# ESP32-S2 register map
Vendor: ESPRESSIF SYSTEMS (SHANGHAI) CO., LTD.; Series: ESP32 S-Series; File version: 20
CPU: Xtensa LX7 r0p0, little endian, no MPU, no FPU, 0 interrupt priority bits
Address unit: 32 bits
Registers are 32-bit, read-write, reset 0x0 unless marked. A register's access mark holds for its fields unless they carry their own. Offsets are from the block's base; [hi:lo] are bit positions.

## UART0 — UART (Universal Asynchronous Receiver-Transmitter) Controller 0
Base 0x3F400000
Same registers: UART1 0x3F410000
0x00 FIFO ro — FIFO data register
  [7:0] RXFIFO_RD_BYTE — UART 0 accesses FIFO via this register.
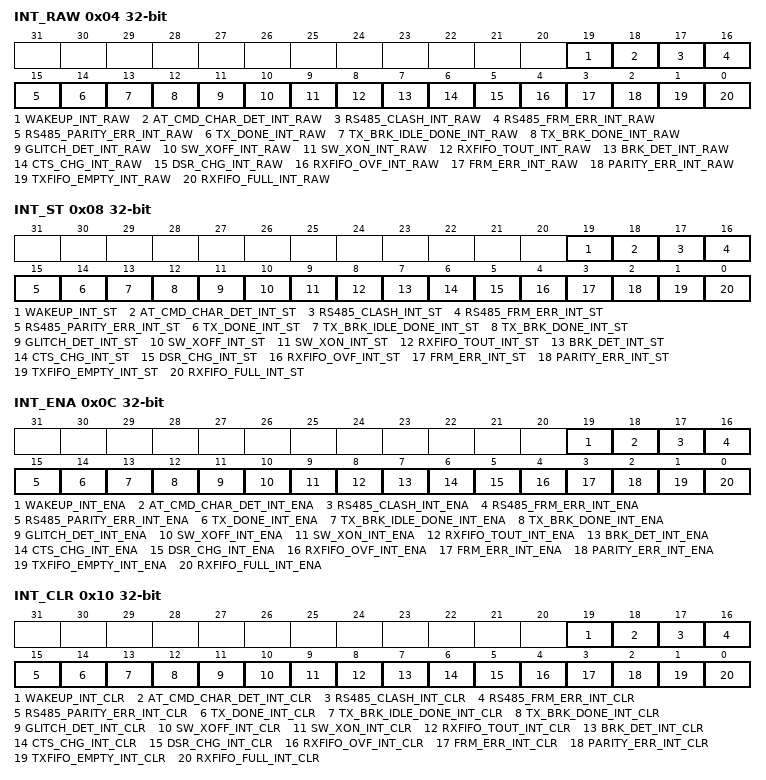
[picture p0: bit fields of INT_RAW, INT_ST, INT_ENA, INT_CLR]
0x04 INT_RAW ro — Raw interrupt status
  [19] WAKEUP_INT_RAW — This interrupt raw bit turns to high level when input RXD edge changes more times than what UART_ACTIVE_THRESHOLD specifies in Light-sleep mode.
  [18] AT_CMD_CHAR_DET_INT_RAW — This interrupt raw bit turns to high level when the receiver detects the configured UART_AT_CMD CHAR.
  [17] RS485_CLASH_INT_RAW — This interrupt raw bit turns to high level when a collision is detected between the transmitter and the receiver in RS485 mode.
  [16] RS485_FRM_ERR_INT_RAW — This interrupt raw bit turns to high level when the receiver detects a data frame error from the echo of the transmitter in RS485 mode.
  [15] RS485_PARITY_ERR_INT_RAW — This interrupt raw bit turns to high level when the receiver detects a parity error from the echo of the transmitter in RS485 mode.
  [14] TX_DONE_INT_RAW — This interrupt raw bit turns to high level when the transmitter has sent out all data in FIFO.
  [13] TX_BRK_IDLE_DONE_INT_RAW — This interrupt raw bit turns to high level when the transmitter has kept the shortest duration after sending the last data.
  [12] TX_BRK_DONE_INT_RAW — This interrupt raw bit turns to high level when the transmitter completes sending NULL characters, after all data in TX FIFO are sent.
  [11] GLITCH_DET_INT_RAW — This interrupt raw bit turns to high level when the receiver detects a glitch in the middle of a start bit.
  [10] SW_XOFF_INT_RAW — This interrupt raw bit turns to high level when the receiver receives an XOFF character and UART_SW_FLOW_CON_EN is set to 1.
  [9] SW_XON_INT_RAW — This interrupt raw bit turns to high level when the receiver receives an XON character and UART_SW_FLOW_CON_EN is set to 1.
  [8] RXFIFO_TOUT_INT_RAW — This interrupt raw bit turns to high level when the receiver takes more time than UART_RX_TOUT_THRHD to receive a byte.
  [7] BRK_DET_INT_RAW — This interrupt raw bit turns to high level when the receiver detects a 0 after the stop bit.
  [6] CTS_CHG_INT_RAW — This interrupt raw bit turns to high level when the receiver detects the edge change of CTSn signal.
  [5] DSR_CHG_INT_RAW — This interrupt raw bit turns to high level when the receiver detects the edge change of DSRn signal.
  [4] RXFIFO_OVF_INT_RAW — This interrupt raw bit turns to high level when the receiver receives more data than the capacity of RX FIFO.
  [3] FRM_ERR_INT_RAW — This interrupt raw bit turns to high level when the receiver detects a data frame error.
  [2] PARITY_ERR_INT_RAW — This interrupt raw bit turns to high level when the receiver detects a parity error in the data.
  [1] TXFIFO_EMPTY_INT_RAW — This interrupt raw bit turns to high level when the amount of data in TX FIFO is less than what UART_TXFIFO_EMPTY_THRHD specifies.
  [0] RXFIFO_FULL_INT_RAW — This interrupt raw bit turns to high level when the receiver receives more data than what UART_RXFIFO_FULL_THRHD specifies.
0x08 INT_ST ro — Masked interrupt status
  [19] WAKEUP_INT_ST — This is the status bit for UART_WAKEUP_INT when UART_WAKEUP_INT_ENA is set to 1.
  [18] AT_CMD_CHAR_DET_INT_ST — This is the status bit for UART_AT_CMD_CHAR_DET_INT when UART_AT_CMD_CHAR_DET_INT_ENA is set to 1.
  [17] RS485_CLASH_INT_ST — This is the status bit for UART_RS485_CLASH_INT when UART_RS485_CLASH_INT_ENA is set to 1.
  [16] RS485_FRM_ERR_INT_ST — This is the status bit for UART_RS485_FRM_ERR_INT when UART_RS485_FRM_ERR_INT_ENA is set to 1.
  [15] RS485_PARITY_ERR_INT_ST — This is the status bit for UART_RS485_PARITY_ERR_INT when UART_RS485_PARITY_INT_ENA is set to 1.
  [14] TX_DONE_INT_ST — This is the status bit for UART_TX_DONE_INT when UART_TX_DONE_INT_ENA is set to 1.
  [13] TX_BRK_IDLE_DONE_INT_ST — This is the status bit for UART_TX_BRK_IDLE_DONE_INT when UART_TX_BRK_IDLE_DONE_INT_ENA is set to 1.
  [12] TX_BRK_DONE_INT_ST — This is the status bit for UART_TX_BRK_DONE_INT when UART_TX_BRK_DONE_INT_ENA is set to 1.
  [11] GLITCH_DET_INT_ST — This is the status bit for UART_GLITCH_DET_INT when UART_GLITCH_DET_INT_ENA is set to 1.
  [10] SW_XOFF_INT_ST — This is the status bit for UART_SW_XOFF_INT when UART_SW_XOFF_INT_ENA is set to 1.
  [9] SW_XON_INT_ST — This is the status bit for UART_SW_XON_INT when UART_SW_XON_INT_ENA is set to 1.
  [8] RXFIFO_TOUT_INT_ST — This is the status bit for UART_RXFIFO_TOUT_INT when UART_RXFIFO_TOUT_INT_ENA is set to 1.
  [7] BRK_DET_INT_ST — This is the status bit for UART_BRK_DET_INT when UART_BRK_DET_INT_ENA is set to 1.
  [6] CTS_CHG_INT_ST — This is the status bit for UART_CTS_CHG_INT when UART_CTS_CHG_INT_ENA is set to 1.
  [5] DSR_CHG_INT_ST — This is the status bit for UART_DSR_CHG_INT when UART_DSR_CHG_INT_ENA is set to 1.
  [4] RXFIFO_OVF_INT_ST — This is the status bit for UART_RXFIFO_OVF_INT when UART_RXFIFO_OVF_INT_ENA is set to 1.
  [3] FRM_ERR_INT_ST — This is the status bit for UART_FRM_ERR_INT when UART_FRM_ERR_INT_ENA is set to 1.
  [2] PARITY_ERR_INT_ST — This is the status bit for UART_PARITY_ERR_INT when UART_PARITY_ERR_INT_ENA is set to 1.
  [1] TXFIFO_EMPTY_INT_ST — This is the status bit for UART_TXFIFO_EMPTY_INT when UART_TXFIFO_EMPTY_INT_ENA is set to 1.
  [0] RXFIFO_FULL_INT_ST — This is the status bit for UART_RXFIFO_FULL_INT when UART_RXFIFO_FULL_INT_ENA is set to 1.
0x0C INT_ENA — Interrupt enable bits
  [19] WAKEUP_INT_ENA — This is the enable bit for UART_WAKEUP_INT.
  [18] AT_CMD_CHAR_DET_INT_ENA — This is the enable bit for UART_AT_CMD_CHAR_DET_INT.
  [17] RS485_CLASH_INT_ENA — This is the enable bit for UART_RS485_CLASH_INT.
  [16] RS485_FRM_ERR_INT_ENA — This is the enable bit for UART_RS485_PARITY_ERR_INT.
  [15] RS485_PARITY_ERR_INT_ENA — This is the enable bit for UART_RS485_PARITY_ERR_INT.
  [14] TX_DONE_INT_ENA — This is the enable bit for UART_TX_DONE_INT.
  [13] TX_BRK_IDLE_DONE_INT_ENA — This is the enable bit for UART_TX_BRK_IDLE_DONE_INT.
  [12] TX_BRK_DONE_INT_ENA — This is the enable bit for UART_TX_BRK_DONE_INT.
  [11] GLITCH_DET_INT_ENA — This is the enable bit for UART_GLITCH_DET_INT.
  [10] SW_XOFF_INT_ENA — This is the enable bit for UART_SW_XOFF_INT.
  [9] SW_XON_INT_ENA — This is the enable bit for UART_SW_XON_INT.
  [8] RXFIFO_TOUT_INT_ENA — This is the enable bit for UART_RXFIFO_TOUT_INT.
  [7] BRK_DET_INT_ENA — This is the enable bit for UART_BRK_DET_INT.
  [6] CTS_CHG_INT_ENA — This is the enable bit for UART_CTS_CHG_INT.
  [5] DSR_CHG_INT_ENA — This is the enable bit for UART_DSR_CHG_INT.
  [4] RXFIFO_OVF_INT_ENA — This is the enable bit for UART_RXFIFO_OVF_INT.
  [3] FRM_ERR_INT_ENA — This is the enable bit for UART_FRM_ERR_INT.
  [2] PARITY_ERR_INT_ENA — This is the enable bit for UART_PARITY_ERR_INT.
  [1] TXFIFO_EMPTY_INT_ENA — This is the enable bit for UART_TXFIFO_EMPTY_INT.
  [0] RXFIFO_FULL_INT_ENA — This is the enable bit for UART_RXFIFO_FULL_INT.
0x10 INT_CLR wo — Interrupt clear bits
  [19] WAKEUP_INT_CLR — Set this bit to clear UART_WAKEUP_INT interrupt.
  [18] AT_CMD_CHAR_DET_INT_CLR — Set this bit to clear UART_AT_CMD_CHAR_DET_INT interrupt.
  [17] RS485_CLASH_INT_CLR — Set this bit to clear UART_RS485_CLASH_INT interrupt.
  [16] RS485_FRM_ERR_INT_CLR — Set this bit to clear UART_RS485_FRM_ERR_INT interrupt.
  [15] RS485_PARITY_ERR_INT_CLR — Set this bit to clear UART_RS485_PARITY_ERR_INT interrupt.
  [14] TX_DONE_INT_CLR — Set this bit to clear UART_TX_DONE_INT interrupt.
  [13] TX_BRK_IDLE_DONE_INT_CLR — Set this bit to clear UART_TX_BRK_IDLE_DONE_INT interrupt.
  [12] TX_BRK_DONE_INT_CLR — Set this bit to clear UART_TX_BRK_DONE_INT interrupt.
  [11] GLITCH_DET_INT_CLR — Set this bit to clear UART_GLITCH_DET_INT interrupt.
  [10] SW_XOFF_INT_CLR — Set this bit to clear UART_SW_XOFF_INT interrupt.
  [9] SW_XON_INT_CLR — Set this bit to clear UART_SW_XON_INT interrupt.
  [8] RXFIFO_TOUT_INT_CLR — Set this bit to clear UART_RXFIFO_TOUT_INT interrupt.
  [7] BRK_DET_INT_CLR — Set this bit to clear UART_BRK_DET_INT interrupt.
  [6] CTS_CHG_INT_CLR — Set this bit to clear UART_CTS_CHG_INT interrupt.
  [5] DSR_CHG_INT_CLR — Set this bit to clear UART_DSR_CHG_INT interrupt.
  [4] RXFIFO_OVF_INT_CLR — Set this bit to clear UART_UART_RXFIFO_OVF_INT interrupt.
  [3] FRM_ERR_INT_CLR — Set this bit to clear UART_FRM_ERR_INT interrupt.
  [2] PARITY_ERR_INT_CLR — Set this bit to clear UART_PARITY_ERR_INT interrupt.
  [1] TXFIFO_EMPTY_INT_CLR — Set this bit to clear UART_TXFIFO_EMPTY_INT interrupt.
  [0] RXFIFO_FULL_INT_CLR — Set this bit to clear UART_THE RXFIFO_FULL_INT interrupt.
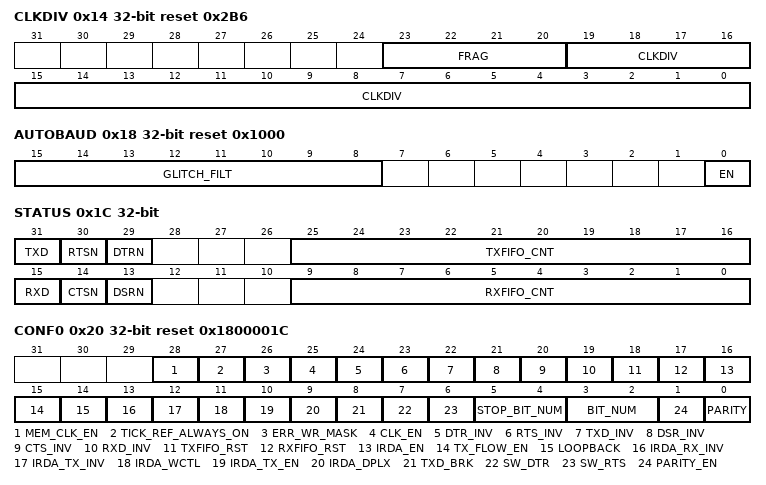
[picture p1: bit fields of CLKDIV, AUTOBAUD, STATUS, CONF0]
0x14 CLKDIV reset 0x2B6 — Clock divider configuration
  [23:20] FRAG — The fractional part of the frequency divisor.
  [19:0] CLKDIV — The integral part of the frequency divisor.
0x18 AUTOBAUD reset 0x1000 — Autobaud configuration register
  [15:8] GLITCH_FILT — When input pulse width is lower than this value, the pulse is ignored. This register is used in autobaud detection.
  [0] EN — This is the enable bit for baud rate detection.
0x1C STATUS ro — UART status register
  [31] TXD — This bit represents the level of the internal UART TXD signal.
  [30] RTSN — This bit represents the level of the internal UART RTS signal.
  [29] DTRN — This bit represents the level of the internal UART DTR signal.
  [25:16] TXFIFO_CNT — Stores the number of data bytes in TX FIFO.
  [15] RXD — This register represents the level of the internal UART RXD signal.
  [14] CTSN — This register represents the level of the internal UART CTS signal.
  [13] DSRN — This register represents the level of the internal UART DSR signal.
  [9:0] RXFIFO_CNT — Stores the number of valid data bytes in RX FIFO.
0x20 CONF0 reset 0x1800001C — Configuration register 0
  [28] MEM_CLK_EN — The signal to enable UART RAM clock gating. 1: UART RAM powers on, the data of which can be read and written. 0: UART RAM powers down.
  [27] TICK_REF_ALWAYS_ON — This register is used to select the clock. 1: APB_CLK. 0: REF_TICK.
  [26] ERR_WR_MASK — 1: The receiver stops storing data into FIFO when data is wrong. 0: The receiver stores the data even if the received data is wrong.
  [25] CLK_EN — 1: Force clock on for registers. 0: Support clock only when application writes registers.
  [24] DTR_INV — Set this bit to invert the level of UART DTR signal.
  [23] RTS_INV — Set this bit to invert the level of UART RTS signal.
  [22] TXD_INV — Set this bit to invert the level of UART TXD signal.
  [21] DSR_INV — Set this bit to invert the level of UART DSR signal.
  [20] CTS_INV — Set this bit to invert the level of UART CTS signal.
  [19] RXD_INV — Set this bit to invert the level of UART RXD signal.
  [18] TXFIFO_RST — Set this bit to reset the UART TX FIFO.
  [17] RXFIFO_RST — Set this bit to reset the UART RX FIFO.
  [16] IRDA_EN — Set this bit to enable IrDA protocol.
  [15] TX_FLOW_EN — Set this bit to enable flow control function for the transmitter.
  [14] LOOPBACK — Set this bit to enable UART loopback test mode.
  [13] IRDA_RX_INV — Set this bit to invert the level of IrDA receiver.
  [12] IRDA_TX_INV — Set this bit to invert the level of IrDA transmitter.
  [11] IRDA_WCTL — 1: The IrDA transmitter's 11th bit is the same as 10th bit. 0: Set IrDA transmitter's 11th bit to 0.
  [10] IRDA_TX_EN — This is the start enable bit for IrDA transmitter.
  [9] IRDA_DPLX — Set this bit to enable IrDA loopback mode.
  [8] TXD_BRK — Set this bit to enable the transmitter to send NULL characters when the process of sending data is done.
  [7] SW_DTR — This register is used to configure the software DTR signal which is used in software flow control.
  [6] SW_RTS — This register is used to configure the software RTS signal which is used in software flow control.
  [5:4] STOP_BIT_NUM — This register is used to set the length of stop bit. 1: 1 bit. 2: 1.5 bits. 3: 2 bits.
  [3:2] BIT_NUM — This register is used to set the length of data. 0: 5 bits. 1: 6 bits. 2: 7 bits. 3: 8 bits.
  [1] PARITY_EN — Set this bit to enable UART parity check.
  [0] PARITY — This register is used to configure the parity check mode. 0: even. 1: odd.
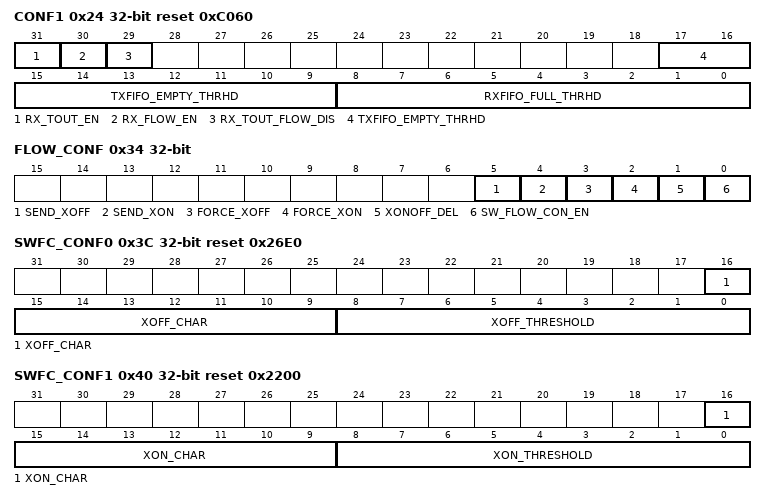
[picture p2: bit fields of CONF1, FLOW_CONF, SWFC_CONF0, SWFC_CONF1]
0x24 CONF1 reset 0xC060 — Configuration register 1
  [31] RX_TOUT_EN — This is the enable bit for UART receiver's timeout function.
  [30] RX_FLOW_EN — This is the flow enable bit for UART receiver. 1: Choose software flow control with configuring sw_rts signal. 0: Disable software flow control.
  [29] RX_TOUT_FLOW_DIS — Set this bit to stop accumulating idle_cnt when hardware flow control works.
  [17:9] TXFIFO_EMPTY_THRHD — An UART_TXFIFO_EMPTY_INT interrupt is generated when the number of data bytes in TX FIFO is less than this register's value.
  [8:0] RXFIFO_FULL_THRHD — An UART_RXFIFO_FULL_INT interrupt is generated when the receiver receives more data than this register’s value.
0x28 LOWPULSE ro reset 0xFFFFF — Autobaud minimum low pulse duration register
  [19:0] MIN_CNT — This register stores the value of the minimum duration time of the low level pulse. It is used in baud rate detection.
0x2C HIGHPULSE ro reset 0xFFFFF — Autobaud minimum high pulse duration register
  [19:0] MIN_CNT — This register stores the value of the maximum duration time for the high level pulse. It is used in baud rate detection.
0x30 RXD_CNT ro — Autobaud edge change count register
  [9:0] RXD_EDGE_CNT — This register stores the count of RXD edge change. It is used in baud rate detection. As baud rate registers UART_REG_LOWPULSE_MIN_CNT, UART_REG_HIGHPULSE_MIN_CNT, UART_REG_POSEDGE_MIN_CNT, and UART_REG_NEGEDGE_MIN_CNT always record the minimal value, UART_REG_RXD_EDGE_CNT indicates the statistic number of RXD edge to find out the minimal value for these baud rate registers.
0x34 FLOW_CONF — Software flow control configuration
  [5] SEND_XOFF — Set this bit to send an XOFF character. This bit is cleared by hardware automatically.
  [4] SEND_XON — Set this bit to send an XON character. This bit is cleared by hardware automatically.
  [3] FORCE_XOFF — Set this bit to stop the transmitter from sending data.
  [2] FORCE_XON — Set this bit to force the transmitter to send data.
  [1] XONOFF_DEL — Set this bit to remove flow control characters from the received data.
  [0] SW_FLOW_CON_EN — Set this bit to enable software flow control. When UART receives flow control characters XON or XOFF, which can be configured by UART_XON_CHAR or UART_XOFF_CHAR respectively, UART_SW_XON_INT or UART_SW_XOFF_INT interrupts can be triggered if enabled.
0x38 SLEEP_CONF reset 0xF0 — Sleep mode configuration
  [9:0] ACTIVE_THRESHOLD — The UART is activated from Light-sleep mode when the input RXD edge changes more times than this register's value.
0x3C SWFC_CONF0 reset 0x26E0 — Software flow control character configuration
  [16:9] XOFF_CHAR — This register stores the XOFF flow control character.
  [8:0] XOFF_THRESHOLD — When the number of data bytes in RX FIFO is more than this register's value with UART_SW_FLOW_CON_EN set to 1, the transmitter sends an XOFF character.
0x40 SWFC_CONF1 reset 0x2200 — Software flow-control character configuration
  [16:9] XON_CHAR — This register stores the XON flow control character.
  [8:0] XON_THRESHOLD — When the number of data bytes in RX FIFO is less than this register's value with UART_SW_FLOW_CON_EN set to 1, the transmitter sends an XON character.
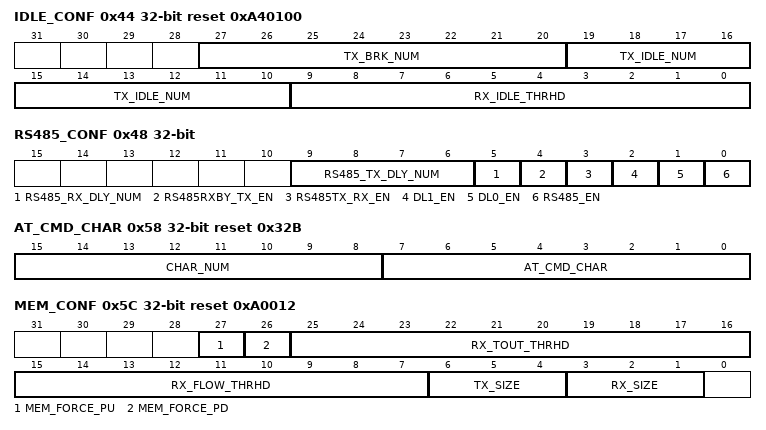
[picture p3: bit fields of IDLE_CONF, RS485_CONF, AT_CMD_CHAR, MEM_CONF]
0x44 IDLE_CONF reset 0xA40100 — Frame end idle time configuration
  [27:20] TX_BRK_NUM — This register is used to configure the number of 0 to be sent after the process of sending data is done. It is active when UART_TXD_BRK is set to 1.
  [19:10] TX_IDLE_NUM — This register is used to configure the duration time between transfers, in the unit of bit time (the time it takes to transfer one bit).
  [9:0] RX_IDLE_THRHD — A frame end signal is generated when the receiver takes more time to receive one byte data than this register's value, in the unit of bit time (the time it takes to transfer one bit).
0x48 RS485_CONF — RS485 mode configuration
  [9:6] RS485_TX_DLY_NUM — This register is used to delay the transmitter's internal data signal.
  [5] RS485_RX_DLY_NUM — This register is used to delay the receiver's internal data signal.
  [4] RS485RXBY_TX_EN — 1: enable RS485 transmitter to send data when RS485 receiver line is busy. 0: RS485 transmitter should not send data when its receiver is busy.
  [3] RS485TX_RX_EN — Set this bit to enable the receiver could receive data when the transmitter is transmitting data in RS485 mode.
  [2] DL1_EN — Set this bit to delay the stop bit by 1 bit.
  [1] DL0_EN — Set this bit to delay the stop bit by 1 bit.
  [0] RS485_EN — Set this bit to choose RS485 mode.
0x4C AT_CMD_PRECNT reset 0x901 — Pre-sequence timing configuration
  [15:0] PRE_IDLE_NUM — This register is used to configure the idle duration time before the first AT_CMD is received by the receiver. It will not take the next data received as AT_CMD character when the duration is less than this register's value.
0x50 AT_CMD_POSTCNT reset 0x901 — Post-sequence timing configuration
  [15:0] POST_IDLE_NUM — This register is used to configure the duration time between the last AT_CMD and the next data. It will not take the previous data as AT_CMD character when the duration is less than this register's value.
0x54 AT_CMD_GAPTOUT reset 0xB — Timeout configuration
  [15:0] RX_GAP_TOUT — This register is used to configure the duration time between the AT_CMD characters. It will not take the data as continuous AT_CMD characters when the duration time is less than this register's value.
0x58 AT_CMD_CHAR reset 0x32B — AT escape sequence selection configuration
  [15:8] CHAR_NUM — This register is used to configure the number of continuous AT_CMD characters received by the receiver.
  [7:0] AT_CMD_CHAR — This register is used to configure the content of AT_CMD character.
0x5C MEM_CONF reset 0xA0012 — UART threshold and allocation configuration
  [27] MEM_FORCE_PU — Set this bit to force power up UART RAM.
  [26] MEM_FORCE_PD — Set this bit to force power down UART RAM.
  [25:16] RX_TOUT_THRHD — This register is used to configure the threshold time that the receiver takes to receive one byte, in the unit of bit time (the time it takes to transfer one bit). The UART_RXFIFO_TOUT_INT interrupt will be triggered when the receiver takes more time to receive one byte with UART RX_TOUT_EN set to 1.
  [15:7] RX_FLOW_THRHD — This register is used to configure the maximum amount of data bytes that can be received when hardware flow control works.
  [6:4] TX_SIZE — This register is used to configure the amount of RAM allocated for TX FIFO. The default number is 128 bytes.
  [3:1] RX_SIZE — This register is used to configure the amount of RAM allocated for RX FIFO. The default number is 128 bytes.
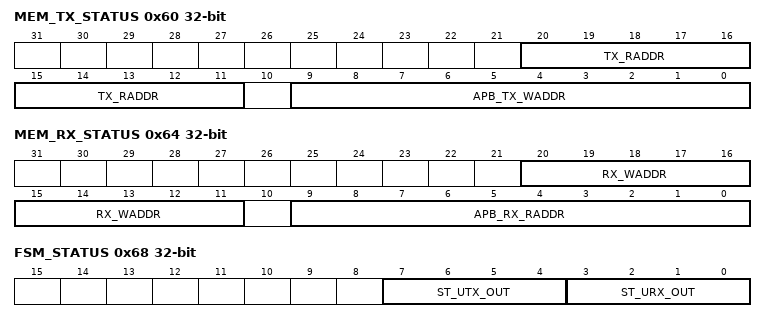
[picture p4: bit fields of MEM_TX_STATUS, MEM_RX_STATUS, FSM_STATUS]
0x60 MEM_TX_STATUS ro — TX FIFO write and read offset address
  [20:11] TX_RADDR — This register stores the offset address in TX FIFO when TX FSM reads data via Tx_FIFO_Ctrl.
  [9:0] APB_TX_WADDR — This register stores the offset address in TX FIFO when software writes TX FIFO via APB.
0x64 MEM_RX_STATUS ro — RX FIFO write and read offset address
  [20:11] RX_WADDR — This register stores the offset address in RX FIFO when Rx_FIFO_Ctrl writes RX FIFO.
  [9:0] APB_RX_RADDR — This register stores the offset address in RX_FIFO when software reads data from RX FIFO via APB.
0x68 FSM_STATUS ro — UART transmitter and receiver status
  [7:4] ST_UTX_OUT — This is the status register of the transmitter.
  [3:0] ST_URX_OUT — This is the status register of the receiver.
0x6C POSPULSE ro reset 0xFFFFF — Autobaud high pulse register
  [19:0] POSEDGE_MIN_CNT — This register stores the minimal input clock count between two positive edges. It is used in baud rate detection.
0x70 NEGPULSE ro reset 0xFFFFF — Autobaud low pulse register
  [19:0] NEGEDGE_MIN_CNT — This register stores the minimal input clock count between two negative edges. It is used in baud rate detection.
0x74 DATE reset 0x18082800 — UART version control register
  [31:0] DATE — This is the version control register.
0x78 ID reset 0x500 — UART ID register
  [31:0] ID — This register is used to configure the UART_ID.
